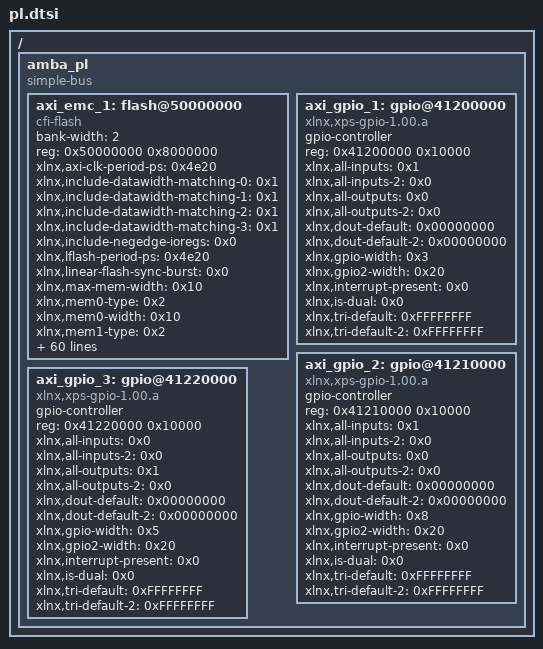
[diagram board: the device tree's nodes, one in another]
/*
 * CAUTION: This file is automatically generated by Xilinx.
 * Version: HSI 
 * Today is: Mon Apr 25 21:09:50 2016
*/


/ {
	amba_pl: amba_pl {
		#address-cells = <1>;
		#size-cells = <1>;
		compatible = "simple-bus";
		ranges ;
		axi_emc_1: flash@50000000 {
			bank-width = <2>;
			compatible = "cfi-flash";
			reg = <0x50000000 0x8000000>;
			xlnx,axi-clk-period-ps = <0x4e20>;
			xlnx,include-datawidth-matching-0 = <0x1>;
			xlnx,include-datawidth-matching-1 = <0x1>;
			xlnx,include-datawidth-matching-2 = <0x1>;
			xlnx,include-datawidth-matching-3 = <0x1>;
			xlnx,include-negedge-ioregs = <0x0>;
			xlnx,lflash-period-ps = <0x4e20>;
			xlnx,linear-flash-sync-burst = <0x0>;
			xlnx,max-mem-width = <0x10>;
			xlnx,mem0-type = <0x2>;
			xlnx,mem0-width = <0x10>;
			xlnx,mem1-type = <0x2>;
			xlnx,mem1-width = <0x10>;
			xlnx,mem2-type = <0x2>;
			xlnx,mem2-width = <0x10>;
			xlnx,mem3-type = <0x2>;
			xlnx,mem3-width = <0x10>;
			xlnx,num-banks-mem = <0x1>;
			xlnx,parity-type-mem-0 = <0x0>;
			xlnx,parity-type-mem-1 = <0x0>;
			xlnx,parity-type-mem-2 = <0x0>;
			xlnx,parity-type-mem-3 = <0x0>;
			xlnx,s-axi-en-reg = <0x0>;
			xlnx,s-axi-mem-addr-width = <0x20>;
			xlnx,s-axi-mem-data-width = <0x20>;
			xlnx,s-axi-mem-id-width = <0xc>;
			xlnx,s-axi-reg-addr-width = <0x5>;
			xlnx,s-axi-reg-data-width = <0x20>;
			xlnx,synch-pipedelay-0 = <0x1>;
			xlnx,synch-pipedelay-1 = <0x1>;
			xlnx,synch-pipedelay-2 = <0x1>;
			xlnx,synch-pipedelay-3 = <0x1>;
			xlnx,tavdv-ps-mem-0 = <0x1fbd0>;
			xlnx,tavdv-ps-mem-1 = <0x3a98>;
			xlnx,tavdv-ps-mem-2 = <0x3a98>;
			xlnx,tavdv-ps-mem-3 = <0x3a98>;
			xlnx,tcedv-ps-mem-0 = <0x1fbd0>;
			xlnx,tcedv-ps-mem-1 = <0x3a98>;
			xlnx,tcedv-ps-mem-2 = <0x3a98>;
			xlnx,tcedv-ps-mem-3 = <0x3a98>;
			xlnx,thzce-ps-mem-0 = <0x88b8>;
			xlnx,thzce-ps-mem-1 = <0x1b58>;
			xlnx,thzce-ps-mem-2 = <0x1b58>;
			xlnx,thzce-ps-mem-3 = <0x1b58>;
			xlnx,thzoe-ps-mem-0 = <0x88b8>;
			xlnx,thzoe-ps-mem-1 = <0x1b58>;
			xlnx,thzoe-ps-mem-2 = <0x1b58>;
			xlnx,thzoe-ps-mem-3 = <0x1b58>;
			xlnx,tlzwe-ps-mem-0 = <0x88b8>;
			xlnx,tlzwe-ps-mem-1 = <0x0>;
			xlnx,tlzwe-ps-mem-2 = <0x0>;
			xlnx,tlzwe-ps-mem-3 = <0x0>;
			xlnx,tpacc-ps-flash-0 = <0x61a8>;
			xlnx,tpacc-ps-flash-1 = <0x61a8>;
			xlnx,tpacc-ps-flash-2 = <0x61a8>;
			xlnx,tpacc-ps-flash-3 = <0x61a8>;
			xlnx,twc-ps-mem-0 = <0x11170>;
			xlnx,twc-ps-mem-1 = <0x3a98>;
			xlnx,twc-ps-mem-2 = <0x3a98>;
			xlnx,twc-ps-mem-3 = <0x3a98>;
			xlnx,twp-ps-mem-0 = <0x2ee0>;
			xlnx,twp-ps-mem-1 = <0x2ee0>;
			xlnx,twp-ps-mem-2 = <0x2ee0>;
			xlnx,twp-ps-mem-3 = <0x2ee0>;
			xlnx,twph-ps-mem-0 = <0x11170>;
			xlnx,twph-ps-mem-1 = <0x2ee0>;
			xlnx,twph-ps-mem-2 = <0x2ee0>;
			xlnx,twph-ps-mem-3 = <0x2ee0>;
			xlnx,wr-rec-time-mem-0 = <0x1017df80>;
			xlnx,wr-rec-time-mem-1 = <0x6978>;
			xlnx,wr-rec-time-mem-2 = <0x6978>;
			xlnx,wr-rec-time-mem-3 = <0x6978>;
		};
		axi_gpio_1: gpio@41200000 {
			#gpio-cells = <2>;
			compatible = "xlnx,xps-gpio-1.00.a";
			gpio-controller ;
			reg = <0x41200000 0x10000>;
			xlnx,all-inputs = <0x1>;
			xlnx,all-inputs-2 = <0x0>;
			xlnx,all-outputs = <0x0>;
			xlnx,all-outputs-2 = <0x0>;
			xlnx,dout-default = <0x00000000>;
			xlnx,dout-default-2 = <0x00000000>;
			xlnx,gpio-width = <0x3>;
			xlnx,gpio2-width = <0x20>;
			xlnx,interrupt-present = <0x0>;
			xlnx,is-dual = <0x0>;
			xlnx,tri-default = <0xFFFFFFFF>;
			xlnx,tri-default-2 = <0xFFFFFFFF>;
		};
		axi_gpio_2: gpio@41210000 {
			#gpio-cells = <2>;
			compatible = "xlnx,xps-gpio-1.00.a";
			gpio-controller ;
			reg = <0x41210000 0x10000>;
			xlnx,all-inputs = <0x1>;
			xlnx,all-inputs-2 = <0x0>;
			xlnx,all-outputs = <0x0>;
			xlnx,all-outputs-2 = <0x0>;
			xlnx,dout-default = <0x00000000>;
			xlnx,dout-default-2 = <0x00000000>;
			xlnx,gpio-width = <0x8>;
			xlnx,gpio2-width = <0x20>;
			xlnx,interrupt-present = <0x0>;
			xlnx,is-dual = <0x0>;
			xlnx,tri-default = <0xFFFFFFFF>;
			xlnx,tri-default-2 = <0xFFFFFFFF>;
		};
		axi_gpio_3: gpio@41220000 {
			#gpio-cells = <2>;
			compatible = "xlnx,xps-gpio-1.00.a";
			gpio-controller ;
			reg = <0x41220000 0x10000>;
			xlnx,all-inputs = <0x0>;
			xlnx,all-inputs-2 = <0x0>;
			xlnx,all-outputs = <0x1>;
			xlnx,all-outputs-2 = <0x0>;
			xlnx,dout-default = <0x00000000>;
			xlnx,dout-default-2 = <0x00000000>;
			xlnx,gpio-width = <0x5>;
			xlnx,gpio2-width = <0x20>;
			xlnx,interrupt-present = <0x0>;
			xlnx,is-dual = <0x0>;
			xlnx,tri-default = <0xFFFFFFFF>;
			xlnx,tri-default-2 = <0xFFFFFFFF>;
		};
	};
};
